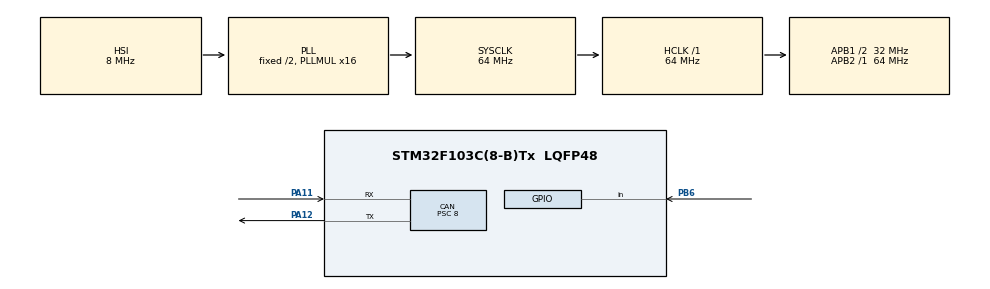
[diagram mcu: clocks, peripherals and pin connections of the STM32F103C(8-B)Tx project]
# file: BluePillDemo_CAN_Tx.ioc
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CAN.BS1=CAN_BS1_5TQ
CAN.BS2=CAN_BS2_3TQ
CAN.CalculateTimeBit=2250
CAN.CalculateTimeQuantum=250.0
CAN.Mode=CAN_MODE_NORMAL
CAN.Prescaler=8
Mcu.Family=STM32F1
Mcu.Name=STM32F103C(8-B)Tx
Mcu.Package=LQFP48
NVIC.PriorityGroup=NVIC_PRIORITYGROUP_4
NVIC.USB_LP_CAN1_RX0_IRQn=true\:0\:0\:false\:false\:true\:true\:true
PA11.Mode=Master
PA11.Signal=CAN_RX
PA12.Mode=Master
PA12.Signal=CAN_TX
PA13.Mode=Serial_Wire
PA13.Signal=SYS_JTMS-SWDIO
PA14.Mode=Serial_Wire
PA14.Signal=SYS_JTCK-SWCLK
PB6.GPIO_PuPd=GPIO_PULLUP
PB6.Signal=GPIO_Input
PC14-OSC32_IN.Mode=LSE-External-Oscillator
PC14-OSC32_IN.Signal=RCC_OSC32_IN
PC15-OSC32_OUT.Mode=LSE-External-Oscillator
PC15-OSC32_OUT.Signal=RCC_OSC32_OUT
PD0-OSC_IN.Mode=HSE-External-Oscillator
PD0-OSC_IN.Signal=RCC_OSC_IN
PD1-OSC_OUT.Mode=HSE-External-Oscillator
PD1-OSC_OUT.Signal=RCC_OSC_OUT
ProjectManager.HeapSize=0x200
ProjectManager.StackSize=0x400
ProjectManager.TargetToolchain=STM32CubeIDE
RCC.AHBFreq_Value=64000000
RCC.APB1CLKDivider=RCC_HCLK_DIV2
RCC.APB1Freq_Value=32000000
RCC.APB1TimFreq_Value=64000000
RCC.APB2Freq_Value=64000000
RCC.APB2TimFreq_Value=64000000
RCC.HCLKFreq_Value=64000000
RCC.PLLMUL=RCC_PLL_MUL16
RCC.SYSCLKFreq_VALUE=64000000
RCC.SYSCLKSource=RCC_SYSCLKSOURCE_PLLCLK
RCC.USBFreq_Value=64000000
board=custom

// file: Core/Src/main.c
/* USER CODE BEGIN Header */
/**
  ******************************************************************************
  * @file           : main.c
  * @brief          : Main program body
  ******************************************************************************
  * @attention
  *
  * <h2><center>&copy; Copyright (c) 2020 STMicroelectronics.
  * All rights reserved.</center></h2>
  *
  * This software component is licensed by ST under BSD 3-Clause license,
  * the "License"; You may not use this file except in compliance with the
  * License. You may obtain a copy of the License at:
  *                        opensource.org/licenses/BSD-3-Clause
  *
  ******************************************************************************
  */
/* USER CODE END Header */

#include "main.h"

CAN_HandleTypeDef hcan;

void SystemClock_Config(void);
static void MX_GPIO_Init(void);
static void MX_CAN_Init(void);

int main(void)
{
  /* USER CODE BEGIN 1 */
  uint8_t tx_data[8] = {0};
  uint32_t tx_mailbox_number;

  /* USER CODE END 1 */

  /* MCU Configuration--------------------------------------------------------*/

  /* Reset of all peripherals, Initializes the Flash interface and the Systick. */
  HAL_Init();

  /* Configure the system clock */
  SystemClock_Config();

  /* Initialize all configured peripherals */
  MX_GPIO_Init();
  MX_CAN_Init();
  /* USER CODE BEGIN 2 */
  // start can
  HAL_CAN_Start(&hcan);

  // setup transmit header
  CAN_TxHeaderTypeDef tx_header;
  tx_header.StdId = 0x555U;
  tx_header.RTR = CAN_RTR_DATA;
  tx_header.IDE = CAN_ID_STD;
  tx_header.DLC = 1U;
  tx_header.TransmitGlobalTime = DISABLE;

  /* USER CODE END 2 */

  /* Infinite loop */
  while (1)
  {

    /* USER CODE BEGIN 3 */
	if (HAL_GPIO_ReadPin(GPIOB, GPIO_PIN_6) == GPIO_PIN_RESET)
	{
	  tx_data[0] = !tx_data[0];
	}
	HAL_CAN_AddTxMessage(&hcan, &tx_header, tx_data, &tx_mailbox_number);
	HAL_Delay(100U);
  }
  /* USER CODE END 3 */
}

void SystemClock_Config(void)
{
  RCC_OscInitTypeDef RCC_OscInitStruct = {0};
  RCC_ClkInitTypeDef RCC_ClkInitStruct = {0};

  /** Initializes the CPU, AHB and APB busses clocks
  */
  RCC_OscInitStruct.OscillatorType = RCC_OSCILLATORTYPE_HSI;
  RCC_OscInitStruct.HSIState = RCC_HSI_ON;
  RCC_OscInitStruct.HSICalibrationValue = RCC_HSICALIBRATION_DEFAULT;
  RCC_OscInitStruct.PLL.PLLState = RCC_PLL_ON;
  RCC_OscInitStruct.PLL.PLLSource = RCC_PLLSOURCE_HSI_DIV2;
  RCC_OscInitStruct.PLL.PLLMUL = RCC_PLL_MUL16;
  if (HAL_RCC_OscConfig(&RCC_OscInitStruct) != HAL_OK)
  {
    Error_Handler();
  }
  /** Initializes the CPU, AHB and APB busses clocks
  */
  RCC_ClkInitStruct.ClockType = RCC_CLOCKTYPE_HCLK|RCC_CLOCKTYPE_SYSCLK
                              |RCC_CLOCKTYPE_PCLK1|RCC_CLOCKTYPE_PCLK2;
  RCC_ClkInitStruct.SYSCLKSource = RCC_SYSCLKSOURCE_PLLCLK;
  RCC_ClkInitStruct.AHBCLKDivider = RCC_SYSCLK_DIV1;
  RCC_ClkInitStruct.APB1CLKDivider = RCC_HCLK_DIV2;
  RCC_ClkInitStruct.APB2CLKDivider = RCC_HCLK_DIV1;

  if (HAL_RCC_ClockConfig(&RCC_ClkInitStruct, FLASH_LATENCY_2) != HAL_OK)
  {
    Error_Handler();
  }
}

static void MX_CAN_Init(void)
{

  hcan.Instance = CAN1;
  hcan.Init.Prescaler = 8;
  hcan.Init.Mode = CAN_MODE_NORMAL;
  hcan.Init.SyncJumpWidth = CAN_SJW_1TQ;
  hcan.Init.TimeSeg1 = CAN_BS1_5TQ;
  hcan.Init.TimeSeg2 = CAN_BS2_3TQ;
  hcan.Init.TimeTriggeredMode = DISABLE;
  hcan.Init.AutoBusOff = DISABLE;
  hcan.Init.AutoWakeUp = DISABLE;
  hcan.Init.AutoRetransmission = DISABLE;
  hcan.Init.ReceiveFifoLocked = DISABLE;
  hcan.Init.TransmitFifoPriority = DISABLE;
  if (HAL_CAN_Init(&hcan) != HAL_OK)
  {
    Error_Handler();
  }

}

static void MX_GPIO_Init(void)
{
  GPIO_InitTypeDef GPIO_InitStruct = {0};

  /* GPIO Ports Clock Enable */
  __HAL_RCC_GPIOC_CLK_ENABLE();
  __HAL_RCC_GPIOD_CLK_ENABLE();
  __HAL_RCC_GPIOA_CLK_ENABLE();
  __HAL_RCC_GPIOB_CLK_ENABLE();

  /*Configure GPIO pin : PB6 */
  GPIO_InitStruct.Pin = GPIO_PIN_6;
  GPIO_InitStruct.Mode = GPIO_MODE_INPUT;
  GPIO_InitStruct.Pull = GPIO_PULLUP;
  HAL_GPIO_Init(GPIOB, &GPIO_InitStruct);

}

void Error_Handler(void)
{
}

/************************ (C) COPYRIGHT STMicroelectronics *****END OF FILE****/
